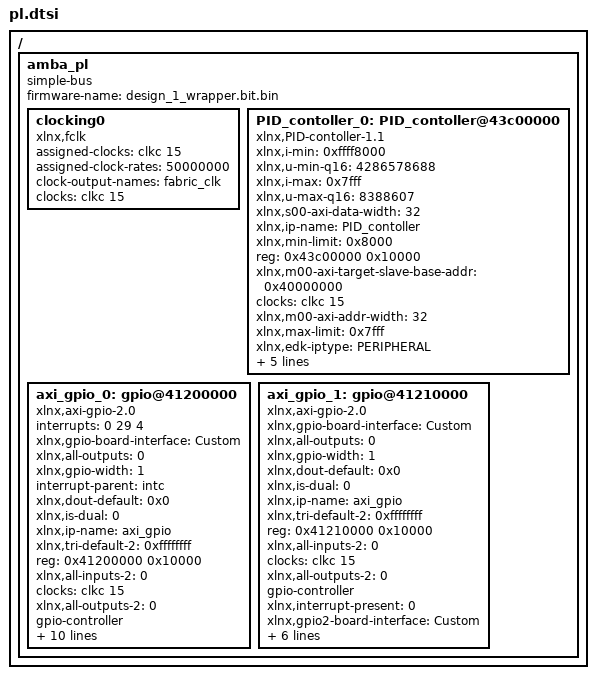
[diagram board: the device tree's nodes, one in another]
/ {
	amba_pl: amba_pl {
		ranges;
		compatible = "simple-bus";
		#address-cells = <1>;
		#size-cells = <1>;
		firmware-name = "design_1_wrapper.bit.bin";
		clocking0: clocking0 {
			compatible = "xlnx,fclk";
			assigned-clocks = <&clkc 15>;
			assigned-clock-rates = <50000000>;
			#clock-cells = <0>;
			clock-output-names = "fabric_clk";
			clocks = <&clkc 15>;
		};
		PID_contoller_0: PID_contoller@43c00000 {
			xlnx,i-min = <0xffff8000>;
			compatible = "xlnx,PID-contoller-1.1";
			xlnx,u-min-q16 = <4286578688>;
			xlnx,i-max = <0x7fff>;
			xlnx,u-max-q16 = <8388607>;
			xlnx,s00-axi-data-width = <32>;
			xlnx,ip-name = "PID_contoller";
			xlnx,min-limit = <0x8000>;
			reg = <0x43c00000 0x10000>;
			xlnx,m00-axi-target-slave-base-addr = <0x40000000>;
			clocks = <&clkc 15>;
			xlnx,m00-axi-addr-width = <32>;
			xlnx,max-limit = <0x7fff>;
			xlnx,edk-iptype = "PERIPHERAL";
			status = "okay";
			clock-names = "s00_axi_aclk";
			xlnx,m00-axi-transactions-num = <4>;
			xlnx,s00-axi-addr-width = <5>;
			xlnx,m00-axi-data-width = <32>;
			xlnx,m00-axi-start-data-value = <0xaa000000>;
			xlnx,name = "PID_contoller_0";
		};
		axi_gpio_0: gpio@41200000 {
			#interrupt-cells = <2>;
			interrupts = < 0 29 4 >;
			xlnx,gpio-board-interface = "Custom";
			compatible = "xlnx,axi-gpio-2.0" , "xlnx,xps-gpio-1.00.a";
			xlnx,all-outputs = <0>;
			#gpio-cells = <2>;
			xlnx,gpio-width = <1>;
			interrupt-parent = <&intc>;
			xlnx,dout-default = <0x0>;
			xlnx,is-dual = <0>;
			xlnx,ip-name = "axi_gpio";
			xlnx,tri-default-2 = <0xffffffff>;
			reg = <0x41200000 0x10000>;
			xlnx,all-inputs-2 = <0>;
			clocks = <&clkc 15>;
			xlnx,all-outputs-2 = <0>;
			gpio-controller;
			xlnx,interrupt-present = <1>;
			xlnx,gpio2-board-interface = "Custom";
			xlnx,edk-iptype = "PERIPHERAL";
			xlnx,dout-default-2 = <0x0>;
			status = "okay";
			xlnx,gpio2-width = <32>;
			clock-names = "s_axi_aclk";
			xlnx,use-board-flow;
			interrupt-controller;
			interrupt-names = "ip2intc_irpt";
			xlnx,tri-default = <0xffffffff>;
			xlnx,name = "axi_gpio_0";
			xlnx,all-inputs = <1>;
		};
		axi_gpio_1: gpio@41210000 {
			xlnx,gpio-board-interface = "Custom";
			compatible = "xlnx,axi-gpio-2.0" , "xlnx,xps-gpio-1.00.a";
			xlnx,all-outputs = <0>;
			#gpio-cells = <2>;
			xlnx,gpio-width = <1>;
			xlnx,dout-default = <0x0>;
			xlnx,is-dual = <0>;
			xlnx,ip-name = "axi_gpio";
			xlnx,tri-default-2 = <0xffffffff>;
			reg = <0x41210000 0x10000>;
			xlnx,all-inputs-2 = <0>;
			clocks = <&clkc 15>;
			xlnx,all-outputs-2 = <0>;
			gpio-controller;
			xlnx,interrupt-present = <0>;
			xlnx,gpio2-board-interface = "Custom";
			xlnx,edk-iptype = "PERIPHERAL";
			xlnx,dout-default-2 = <0x0>;
			status = "okay";
			xlnx,gpio2-width = <32>;
			clock-names = "s_axi_aclk";
			xlnx,tri-default = <0xffffffff>;
			xlnx,name = "axi_gpio_1";
			xlnx,all-inputs = <1>;
		};
	};
};
